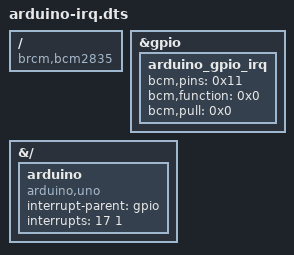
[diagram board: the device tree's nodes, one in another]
/dts-v1/;
/plugin/;

/ {
	compatible = "brcm,bcm2835";
};

&gpio {
	arduino_gpio_irq: arduino_gpio_irq {
		bcm,pins = <0x11>;
		bcm,function = <0x0>;
		bcm,pull = <0x0>;
	};
};

&{/} {
	arduino: arduino {
		compatible = "arduino,uno";
		interrupt-parent = <&gpio>;
		interrupts = <17 1>;
		status = "ok";
	};
};
